# STM32U031 register map
File version: 1.0
CPU: CM0+ r0p1, little endian, MPU, no FPU, 4 interrupt priority bits
Registers are 32-bit, read-write, reset 0x0 unless marked. A register's access mark holds for its fields unless they carry their own. Offsets are from the block's base; [hi:lo] are bit positions; {n}, {i} and the like mark numbered series.

## DAC — DAC address block description
Base 0x40007400
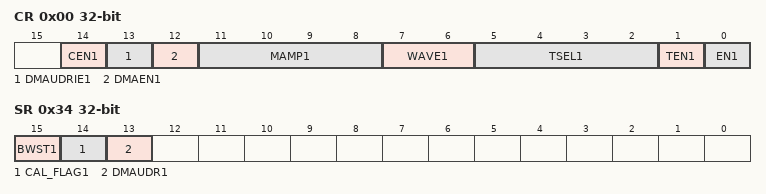
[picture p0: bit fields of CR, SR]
0x00 CR — DAC control register
  [n+13] CEN{n} (n=1..1) — DAC channel{n} calibration enable
    0=Normal (DAC Channel X Normal operating mode); 1=Calibration (DAC Channel X calibration mode)
  [n+12] DMAUDRIE{n} (n=1..1) — DAC channel{n} DMA Underrun Interrupt enable
    0=Disabled (DAC channel X DMA Underrun Interrupt disabled); 1=Enabled (DAC channel X DMA Underrun Interrupt enabled)
  [n+11] DMAEN{n} (n=1..1) — DAC channel{n} DMA enable
    0=Disabled (DAC Channel X DMA mode disabled); 1=Enabled (DAC Channel X DMA mode enabled)
  [n+10:n+7] MAMP{n} (n=1..1) — DAC channel{n} mask/amplitude selector
    0=Amp1 (Unmask bit0 of LFSR/ triangle amplitude equal to 1); 1=Amp3 (Unmask bits[1:0] of LFSR/ triangle amplitude equal to 3); 2=Amp7 (Unmask bits[2:0] of LFSR/ triangle amplitude equal to 7); 3=Amp15 (Unmask bits[3:0] of LFSR/ triangle amplitude equal to 15); 4=Amp31 (Unmask bits[4:0] of LFSR/ triangle amplitude equal to 31); 5=Amp63 (Unmask bits[5:0] of LFSR/ triangle amplitude equal 63); 6=Amp127 (Unmask bits[6:0] of LFSR/ triangle amplitude equal to 127); 7=Amp255 (Unmask bits[7:0] of LFSR/ triangle amplitude equal to 255); 8=Amp511 (Unmask bits[8:0] of LFSR/ triangle amplitude equal to 511); 9=Amp1023 (Unmask bits[9:0] of LFSR/ triangle amplitude equal to 1023); 10=Amp2047 (Unmask bits[10:0] of LFSR/ triangle amplitude equal to 2047); other=Amp4095 (Unmask bits[11:0] of LFSR/ triangle amplitude equal to 4095)
  [n+6:n+5] WAVE{n} (n=1..1) — DAC channel{n} noise/triangle wave generation enable
    0=Disabled (Wave generation disabled); 1=Noise wave generation enabled; other=Triangle wave generation enabled
  [5:2] TSEL1 — DAC channel1 trigger selection These bits select the external event used to trigger DAC channel1 ... Refer to the trigger selection tables in Section114.4.2: DAC pins and internal signals for details on trigger configuration and mapping. Note: Only used if bit TEN11=11 (DAC channel1 trigger enabled).
    0=Swtrig (Software trigger); 1=Tim1Trgo (Timer 1 TRGO event); 2=Tim2Trgo (Timer 2 TRGO event); 3=Tim3Trgo (Timer 3 TRGO event); 5=Tim6Trgo (Timer 6 TRGO event); 6=Tim7Trgo (Timer 7 TRGO event); 8=Tim15Trgo (Timer 15 TRGO event); 11=LPTIM1 OUT event; 12=LPTIM2 OUT event; 14=Exti9 (EXTI line 9)
  [n] TEN{n} (n=1..1) — DAC channel{n} trigger enable
    0=Disabled (DAC Channel X trigger disabled); 1=Enabled (DAC Channel X trigger enabled)
  [n-1] EN{n} (n=1..1) — DAC channel{n} enable
    0=Disabled (DAC Channel X disabled); 1=Enabled (DAC Channel X enabled)
0x04 SWTRGR wo — DAC software trigger register
  [n-1] SWTRIG{n} (n=1..1) — DAC channel{n} software trigger
    0=NoTrigger; 1=Trigger
{0x4+4i} DHR12R{i} (i=1..1) — channel{i} 12-bit right-aligned data holding register
  [11:0] DACCDHR — DAC channel1 12-bit right-aligned data These bits are written by software. They specify 12-bit data for DAC channel1.
{0x8+4i} DHR12L{i} (i=1..1) — channel{i} 12-bit left aligned data holding register
  [15:4] DACCDHR — DAC channel1 12-bit left-aligned data These bits are written by software. They specify 12-bit data for DAC channel1.
{0xC+4i} DHR8R{i} (i=1..1) — channel{i} 8-bit right aligned data holding register
  [7:0] DACCDHR — DAC channel1 8-bit right-aligned data These bits are written by software. They specify 8-bit data for DAC channel1.
{0x28+4i} DOR{i} (i=1..1) ro — channel{i} data output register
  [11:0] DACCDOR — DAC channel1 data output These bits are read-only, they contain data output for DAC channel1.
0x34 SR access per field — DAC status register
  [n+14] BWST{n} (n=1..1) ro — DAC channel{n} busy writing sample time flag
    0=Idle (There is no write operation of DAC_SHSR1 ongoing: DAC_SHSR1 can be written); 1=Busy (There is a write operation of DAC_SHSR1 ongoing: DAC_SHSR1 cannot be written)
  [n+13] CAL_FLAG{n} (n=1..1) ro — DAC channel{n} calibration offset status
    0=Lower (Calibration trimming value is lower than the offset correction value); 1=Equal_Higher (Calibration trimming value is equal or greater than the offset correction value)
  [n+12] DMAUDR{n} (n=1..1) rw — DAC channel{n} DMA underrun flag
    0=NoUnderrun (No DMA underrun error condition occurred for DAC channel x); 1=Underrun (DMA underrun error condition occurred for DAC channel x (the currently selected trigger is driving DAC channel1 conversion at a frequency higher than the DMA service capability rate))
0x38 CCR (reset mask 0xFFFFFF00) — DAC calibration control register
  [n+3:n-1] OTRIM{n} (n=1..1) — DAC channel{n} offset trimming value
0x3C MCR — DAC mode control register
  [n+1:n-1] MODE{n} (n=1..1) — DAC channel{n} mode
    0=NormalPinBuffer (Normal mode - DAC channelx is connected to external pin with Buffer enabled); 1=NormalPinChipBuffer (Normal mode - DAC channelx is connected to external pin and to on chip peripherals with Buffer enabled); 2=NormalPinNoBuffer (Normal mode - DAC channelx is connected to external pin with Buffer disabled); 3=NormalChipNoBuffer (Normal mode - DAC channelx is connected to on chip peripherals with Buffer disabled); 4=SHPinBuffer (S&H mode - DAC channelx is connected to external pin with Buffer enabled); 5=SHPinChipBuffer (S&H mode - DAC channelx is connected to external pin and to on chip peripherals with Buffer enabled); 6=SHPinNoBuffer (S&H mode - DAC channelx is connected to external pin and to on chip peripherals with Buffer disabled); 7=SHChipNoBuffer (S&H mode - DAC channelx is connected to on chip peripherals with Buffer disabled)
{0x3C+4i} SHSR{i} (i=1..1) — DAC channel{i} sample and hold sample time register
  [9:0] TSAMPLE — DAC channel1 sample time (only valid in Sample and hold mode) These bits can be written when the DAC channel1 is disabled or also during normal operation. in the latter case, the write can be done only when BWST1 of DAC_SR register is low, If BWST11=11, the write operation is ignored.
0x48 SHHR reset 0x10001 — DAC sample and hold time register
  [n+8:n-1] THOLD{n} (n=1..1) — DAC channel{n} hold time (only valid in Sample and hold mode)
0x4C SHRR reset 0x10001 — DAC sample and hold refresh time register
  [n+6:n-1] TREFRESH{n} (n=1..1) — DAC channel{n} refresh time (only valid in Sample and hold mode)
